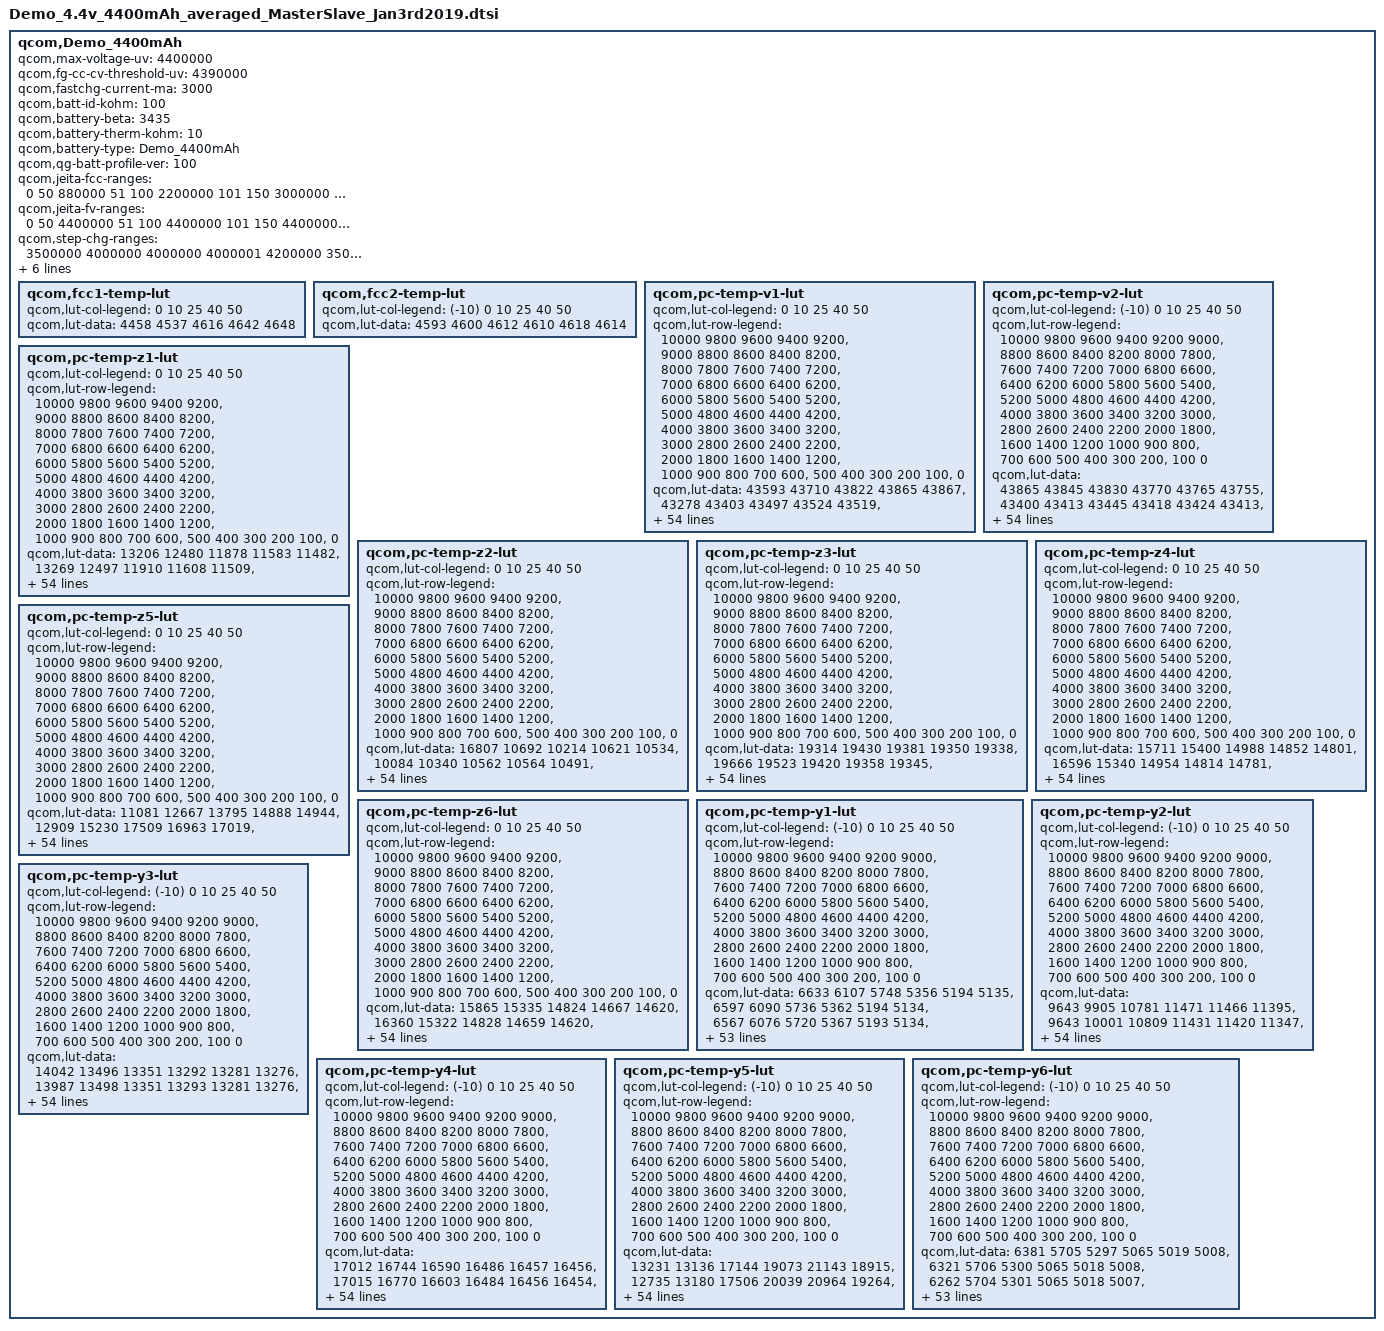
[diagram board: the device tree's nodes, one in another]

qcom,Demo_4400mAh {
    /* Demo */
    qcom,max-voltage-uv = <4400000>;
    qcom,fg-cc-cv-threshold-uv = <4390000>;
    qcom,fastchg-current-ma = <3000>;
    qcom,batt-id-kohm = <100>;
    qcom,battery-beta = <3435>;
    qcom,battery-therm-kohm = <10>;
    qcom,battery-type = "Demo_4400mAh";
    qcom,qg-batt-profile-ver = <100>;

	qcom,jeita-fcc-ranges = <0  50  880000
				51 100  2200000
				101 150  3000000
				151 450  4400000
				451 600  2200000>;

	qcom,jeita-fv-ranges = <0   50  4400000
				51 100  4400000
				101 150  4400000
				151 450  4400000
				451 600  4100000>;

	qcom,step-chg-ranges = <3500000  4000000  4000000
				4000001  4200000  3500000
				4200001  4400000  2500000>;
	qcom,ocv-based-step-chg;

	/* COOL = 10 degc, WARM = 45 degC */
	qcom,jeita-soft-thresholds = <0x2AEE 0x0FB3>;
	/* COLD = 0 degC, HOT = 60 degC*/
	qcom,jeita-hard-thresholds = <0x3733 0x0A34>;
	/* COOL hys = 13 degC, WARM hys = 42 degC */
	qcom,jeita-soft-hys-thresholds = <0x279A 0x1124>;
	qcom,jeita-soft-fcc-ua = <2200000 2200000>;
	qcom,jeita-soft-fv-uv = <4400000 4100000>;
	qcom,fcc1-temp-lut {
		qcom,lut-col-legend = <0 10 25 40 50>;
		qcom,lut-data = <4458 4537 4616 4642 4648>;
	};

	qcom,fcc2-temp-lut {
		qcom,lut-col-legend = <(-10) 0 10 25 40 50>;
		qcom,lut-data = <4593 4600 4612 4610 4618 4614>;
	};

	qcom,pc-temp-v1-lut {
		qcom,lut-col-legend = <0 10 25 40 50>;
		qcom,lut-row-legend = <10000 9800 9600 9400 9200>,
			<9000 8800 8600 8400 8200>,
			<8000 7800 7600 7400 7200>,
			<7000 6800 6600 6400 6200>,
			<6000 5800 5600 5400 5200>,
			<5000 4800 4600 4400 4200>,
			<4000 3800 3600 3400 3200>,
			<3000 2800 2600 2400 2200>,
			<2000 1800 1600 1400 1200>,
			<1000 900 800 700 600>,
			<500 400 300 200 100>,
			<0>;
		qcom,lut-data = <43593 43710 43822 43865 43867>,
			<43278 43403 43497 43524 43519>,
			<43007 43121 43220 43244 43242>,
			<42753 42870 42964 42991 42990>,
			<42511 42627 42716 42746 42749>,
			<42282 42387 42472 42504 42509>,
			<42060 42154 42233 42267 42272>,
			<41848 41931 41998 42031 42037>,
			<41642 41716 41768 41799 41807>,
			<41441 41507 41544 41571 41582>,
			<41244 41306 41328 41347 41359>,
			<41047 41108 41121 41127 41138>,
			<40854 40907 40912 40912 40921>,
			<40642 40707 40702 40705 40713>,
			<40358 40483 40494 40504 40510>,
			<40060 40203 40286 40313 40318>,
			<39877 39966 40076 40129 40135>,
			<39759 39837 39902 39955 39960>,
			<39650 39741 39766 39793 39795>,
			<39534 39626 39637 39639 39637>,
			<39419 39499 39503 39495 39489>,
			<39305 39359 39357 39351 39345>,
			<39190 39199 39149 39166 39165>,
			<39075 39023 38857 38909 38915>,
			<38960 38828 38661 38700 38705>,
			<38844 38613 38572 38585 38581>,
			<38722 38483 38503 38495 38484>,
			<38595 38420 38430 38403 38390>,
			<38491 38374 38359 38313 38303>,
			<38408 38333 38294 38235 38224>,
			<38341 38298 38234 38167 38154>,
			<38291 38265 38181 38107 38090>,
			<38252 38232 38134 38056 38035>,
			<38222 38201 38092 38010 37983>,
			<38202 38172 38056 37969 37935>,
			<38181 38143 38024 37933 37891>,
			<38155 38112 37990 37892 37843>,
			<38123 38083 37957 37849 37793>,
			<38082 38041 37915 37797 37734>,
			<38026 37964 37845 37726 37658>,
			<37953 37858 37743 37634 37561>,
			<37844 37745 37633 37527 37452>,
			<37702 37613 37504 37398 37326>,
			<37553 37454 37348 37243 37171>,
			<37396 37293 37188 37085 37016>,
			<37265 37179 37079 36988 36928>,
			<37224 37146 37051 36960 36902>,
			<37194 37120 37032 36941 36882>,
			<37167 37104 37015 36927 36868>,
			<37139 37086 36991 36901 36837>,
			<37042 36976 36857 36737 36650>,
			<36672 36598 36470 36334 36237>,
			<36117 36046 35910 35772 35673>,
			<35362 35287 35145 35006 34903>,
			<34197 34121 33968 33826 33718>,
			<30000 30000 30000 30000 30000>;
	};

	qcom,pc-temp-v2-lut {
		qcom,lut-col-legend = <(-10) 0 10 25 40 50>;
		qcom,lut-row-legend = <10000 9800 9600 9400 9200 9000>,
			<8800 8600 8400 8200 8000 7800>,
			<7600 7400 7200 7000 6800 6600>,
			<6400 6200 6000 5800 5600 5400>,
			<5200 5000 4800 4600 4400 4200>,
			<4000 3800 3600 3400 3200 3000>,
			<2800 2600 2400 2200 2000 1800>,
			<1600 1400 1200 1000 900 800>,
			<700 600 500 400 300 200>,
			<100 0>;
		qcom,lut-data = <43865 43845 43830 43770 43765 43755>,
			<43400 43413 43445 43418 43424 43413>,
			<42997 43037 43103 43101 43115 43104>,
			<42665 42728 42811 42824 42840 42830>,
			<42385 42468 42560 42580 42595 42587>,
			<42134 42222 42316 42341 42356 42348>,
			<41909 41988 42074 42103 42118 42111>,
			<41695 41758 41839 41870 41884 41878>,
			<41462 41503 41613 41641 41654 41648>,
			<41233 41249 41394 41417 41428 41422>,
			<41091 41087 41191 41199 41206 41200>,
			<41019 40995 41008 40989 40988 40983>,
			<40912 40875 40812 40781 40776 40770>,
			<40482 40576 40572 40568 40571 40566>,
			<39911 40196 40318 40355 40372 40367>,
			<39630 39939 40092 40149 40181 40177>,
			<39459 39735 39881 39948 39999 39994>,
			<39295 39550 39714 39781 39827 39821>,
			<39126 39377 39591 39647 39664 39658>,
			<38962 39202 39457 39510 39507 39501>,
			<38799 39014 39248 39346 39360 39354>,
			<38642 38821 39000 39167 39210 39204>,
			<38513 38641 38801 38966 39012 39010>,
			<38402 38465 38631 38734 38757 38758>,
			<38309 38328 38485 38546 38559 38559>,
			<38232 38235 38360 38416 38430 38430>,
			<38166 38162 38249 38309 38326 38325>,
			<38104 38101 38145 38213 38229 38228>,
			<38047 38048 38050 38128 38143 38140>,
			<37995 38001 37981 38051 38065 38061>,
			<37946 37959 37930 37981 37995 37989>,
			<37898 37920 37889 37918 37931 37924>,
			<37851 37881 37856 37864 37878 37871>,
			<37803 37843 37828 37816 37827 37819>,
			<37755 37806 37799 37775 37771 37759>,
			<37706 37769 37769 37739 37712 37689>,
			<37652 37727 37735 37698 37645 37610>,
			<37593 37677 37698 37648 37567 37514>,
			<37527 37619 37652 37589 37486 37419>,
			<37456 37553 37584 37518 37411 37341>,
			<37379 37474 37491 37434 37334 37267>,
			<37302 37377 37376 37342 37248 37182>,
			<37225 37261 37245 37226 37138 37075>,
			<37144 37126 37100 37092 37008 36945>,
			<37058 36992 36965 36930 36856 36798>,
			<36970 36900 36871 36872 36810 36756>,
			<36929 36867 36840 36855 36802 36749>,
			<36881 36842 36815 36842 36788 36738>,
			<36814 36810 36781 36817 36769 36718>,
			<36709 36751 36715 36778 36723 36669>,
			<36492 36605 36558 36625 36536 36444>,
			<36101 36215 36161 36189 36065 35966>,
			<35511 35602 35539 35583 35445 35337>,
			<34647 34730 34674 34766 34599 34480>,
			<33223 33339 33371 33530 33340 33177>,
			<30321 29646 29628 28797 29074 28973>;
	};

	qcom,pc-temp-z1-lut {
		qcom,lut-col-legend = <0 10 25 40 50>;
		qcom,lut-row-legend = <10000 9800 9600 9400 9200>,
			<9000 8800 8600 8400 8200>,
			<8000 7800 7600 7400 7200>,
			<7000 6800 6600 6400 6200>,
			<6000 5800 5600 5400 5200>,
			<5000 4800 4600 4400 4200>,
			<4000 3800 3600 3400 3200>,
			<3000 2800 2600 2400 2200>,
			<2000 1800 1600 1400 1200>,
			<1000 900 800 700 600>,
			<500 400 300 200 100>,
			<0>;
		qcom,lut-data = <13206 12480 11878 11583 11482>,
			<13269 12497 11910 11608 11509>,
			<13266 12498 11904 11604 11507>,
			<13261 12478 11895 11598 11501>,
			<13248 12463 11883 11592 11499>,
			<13225 12454 11874 11588 11498>,
			<13207 12449 11864 11584 11496>,
			<13190 12443 11858 11579 11494>,
			<13176 12438 11856 11577 11493>,
			<13166 12434 11856 11575 11492>,
			<13157 12427 11857 11574 11491>,
			<13142 12422 11861 11573 11490>,
			<13109 12415 11862 11572 11489>,
			<13079 12401 11846 11570 11488>,
			<13057 12386 11827 11567 11488>,
			<13037 12366 11826 11567 11487>,
			<13026 12355 11829 11568 11488>,
			<13014 12363 11832 11570 11489>,
			<13009 12377 11840 11573 11491>,
			<13017 12381 11848 11575 11492>,
			<13028 12385 11853 11575 11493>,
			<13030 12389 11857 11576 11494>,
			<13029 12398 11859 11577 11495>,
			<13029 12408 11860 11579 11497>,
			<13042 12412 11862 11582 11499>,
			<13060 12414 11867 11585 11501>,
			<13064 12417 11872 11587 11504>,
			<13072 12421 11875 11590 11507>,
			<13076 12425 11877 11593 11509>,
			<13086 12431 11881 11597 11511>,
			<13098 12436 11888 11600 11514>,
			<13100 12441 11894 11603 11516>,
			<13104 12447 11897 11608 11518>,
			<13105 12451 11898 11612 11521>,
			<13105 12456 11903 11615 11523>,
			<13109 12467 11912 11617 11525>,
			<13124 12476 11916 11619 11527>,
			<13151 12486 11917 11625 11530>,
			<13159 12497 11918 11630 11533>,
			<13156 12511 11927 11634 11536>,
			<13156 12525 11941 11637 11539>,
			<13181 12536 11945 11640 11542>,
			<13214 12543 11945 11644 11544>,
			<13204 12534 11951 11647 11545>,
			<13197 12531 11961 11649 11547>,
			<13199 12533 11962 11654 11549>,
			<13204 12542 11958 11655 11549>,
			<13170 12535 11962 11655 11549>,
			<13212 12545 11968 11656 11551>,
			<13187 12555 11964 11658 11555>,
			<13207 12547 11972 11666 11560>,
			<13187 12580 11984 11675 11567>,
			<13209 12595 11997 11684 11576>,
			<13255 12620 12017 11698 11586>,
			<13255 12620 12017 11698 11586>,
			<13255 12620 12017 11698 11586>;
	};

	qcom,pc-temp-z2-lut {
		qcom,lut-col-legend = <0 10 25 40 50>;
		qcom,lut-row-legend = <10000 9800 9600 9400 9200>,
			<9000 8800 8600 8400 8200>,
			<8000 7800 7600 7400 7200>,
			<7000 6800 6600 6400 6200>,
			<6000 5800 5600 5400 5200>,
			<5000 4800 4600 4400 4200>,
			<4000 3800 3600 3400 3200>,
			<3000 2800 2600 2400 2200>,
			<2000 1800 1600 1400 1200>,
			<1000 900 800 700 600>,
			<500 400 300 200 100>,
			<0>;
		qcom,lut-data = <16807 10692 10214 10621 10534>,
			<10084 10340 10562 10564 10491>,
			<10152 10364 10577 10621 10493>,
			<10192 10326 10558 10654 10658>,
			<10226 10285 10528 10627 10601>,
			<10253 10254 10494 10592 10547>,
			<10265 10226 10457 10553 10532>,
			<10270 10206 10435 10516 10524>,
			<10272 10188 10436 10510 10489>,
			<10262 10181 10441 10518 10414>,
			<10240 10179 10447 10523 10385>,
			<10213 10178 10457 10534 10394>,
			<10173 10186 10468 10544 10408>,
			<10134 10213 10490 10542 10426>,
			<10095 10238 10513 10533 10449>,
			<10062 10257 10514 10512 10462>,
			<10059 10279 10509 10468 10470>,
			<10075 10318 10509 10448 10480>,
			<10091 10365 10535 10465 10506>,
			<10103 10394 10565 10493 10538>,
			<10114 10411 10584 10514 10550>,
			<10125 10428 10598 10535 10557>,
			<10136 10454 10593 10562 10591>,
			<10148 10475 10573 10607 10709>,
			<10163 10467 10561 10622 10777>,
			<10180 10435 10554 10587 10774>,
			<10201 10423 10550 10557 10787>,
			<10229 10440 10566 10583 10749>,
			<10252 10460 10600 10636 10602>,
			<10268 10471 10607 10648 10484>,
			<10283 10479 10594 10593 10401>,
			<10300 10488 10584 10551 10357>,
			<10319 10498 10581 10553 10363>,
			<10336 10508 10580 10558 10383>,
			<10352 10519 10589 10568 10414>,
			<10369 10532 10620 10593 10470>,
			<10395 10547 10641 10624 10528>,
			<10427 10564 10651 10671 10594>,
			<10437 10584 10662 10707 10642>,
			<10338 10611 10695 10712 10653>,
			<10255 10636 10736 10711 10659>,
			<10281 10645 10742 10722 10663>,
			<10334 10650 10738 10749 10671>,
			<10423 10664 10742 10760 10665>,
			<11474 10742 10765 10768 10650>,
			<15092 10949 10832 10732 10650>,
			<14674 10971 10831 10732 10667>,
			<15316 10984 10830 10727 10677>,
			<14764 11173 10832 10752 10725>,
			<15671 19194 10849 10857 10859>,
			<15114 12650 10940 10793 10686>,
			<12745 11170 10916 10633 10499>,
			<13826 11349 10885 10578 10423>,
			<12390 11112 10801 10526 10346>,
			<12390 11112 10801 10526 10346>,
			<12390 11112 10801 10526 10346>;
	};

	qcom,pc-temp-z3-lut {
		qcom,lut-col-legend = <0 10 25 40 50>;
		qcom,lut-row-legend = <10000 9800 9600 9400 9200>,
			<9000 8800 8600 8400 8200>,
			<8000 7800 7600 7400 7200>,
			<7000 6800 6600 6400 6200>,
			<6000 5800 5600 5400 5200>,
			<5000 4800 4600 4400 4200>,
			<4000 3800 3600 3400 3200>,
			<3000 2800 2600 2400 2200>,
			<2000 1800 1600 1400 1200>,
			<1000 900 800 700 600>,
			<500 400 300 200 100>,
			<0>;
		qcom,lut-data = <19314 19430 19381 19350 19338>,
			<19666 19523 19420 19358 19345>,
			<19740 19600 19440 19371 19348>,
			<19774 19615 19463 19399 19378>,
			<19766 19619 19464 19400 19382>,
			<19744 19618 19464 19401 19383>,
			<19726 19615 19463 19400 19384>,
			<19708 19610 19460 19399 19384>,
			<19695 19602 19455 19396 19381>,
			<19694 19595 19449 19389 19370>,
			<19696 19591 19446 19383 19363>,
			<19697 19586 19444 19380 19362>,
			<19693 19573 19440 19377 19361>,
			<19694 19549 19432 19375 19359>,
			<19717 19541 19422 19372 19357>,
			<19750 19543 19419 19368 19354>,
			<19748 19546 19419 19363 19349>,
			<19704 19526 19418 19358 19344>,
			<19664 19492 19415 19355 19341>,
			<19641 19486 19411 19352 19339>,
			<19625 19492 19407 19349 19336>,
			<19623 19498 19404 19347 19333>,
			<19624 19507 19406 19348 19334>,
			<19625 19517 19416 19355 19340>,
			<19634 19519 19420 19358 19343>,
			<19645 19519 19411 19352 19351>,
			<19651 19519 19402 19345 19364>,
			<19656 19519 19406 19355 19370>,
			<19657 19518 19418 19384 19378>,
			<19652 19516 19426 19395 19377>,
			<19645 19513 19431 19392 19372>,
			<19639 19511 19433 19388 19366>,
			<19633 19508 19431 19383 19361>,
			<19624 19505 19426 19377 19357>,
			<19611 19502 19421 19371 19351>,
			<19597 19499 19417 19365 19345>,
			<19587 19495 19413 19361 19341>,
			<19578 19489 19409 19359 19338>,
			<19560 19486 19406 19357 19337>,
			<19478 19485 19404 19354 19337>,
			<19410 19484 19402 19350 19338>,
			<19406 19482 19399 19348 19338>,
			<19403 19477 19395 19348 19337>,
			<19312 19471 19394 19350 19340>,
			<19259 19459 19391 19352 19343>,
			<19257 19424 19379 19341 19332>,
			<19257 19417 19374 19336 19327>,
			<19257 19416 19368 19334 19324>,
			<19257 19343 19365 19330 19315>,
			<19257 19267 19364 19321 19308>,
			<19257 19259 19349 19331 19328>,
			<19258 19324 19351 19345 19340>,
			<19257 19264 19346 19346 19342>,
			<19257 19260 19347 19347 19342>,
			<19257 19260 19347 19347 19342>,
			<19257 19260 19347 19347 19342>;
	};

	qcom,pc-temp-z4-lut {
		qcom,lut-col-legend = <0 10 25 40 50>;
		qcom,lut-row-legend = <10000 9800 9600 9400 9200>,
			<9000 8800 8600 8400 8200>,
			<8000 7800 7600 7400 7200>,
			<7000 6800 6600 6400 6200>,
			<6000 5800 5600 5400 5200>,
			<5000 4800 4600 4400 4200>,
			<4000 3800 3600 3400 3200>,
			<3000 2800 2600 2400 2200>,
			<2000 1800 1600 1400 1200>,
			<1000 900 800 700 600>,
			<500 400 300 200 100>,
			<0>;
		qcom,lut-data = <15711 15400 14988 14852 14801>,
			<16596 15340 14954 14814 14781>,
			<16325 15573 14926 14776 14746>,
			<15993 15355 14992 14852 14812>,
			<15783 15152 14910 14820 14791>,
			<15607 15048 14847 14784 14764>,
			<15470 14969 14809 14762 14742>,
			<15362 14909 14779 14743 14725>,
			<15272 14863 14753 14730 14719>,
			<15194 14827 14732 14721 14716>,
			<15127 14798 14721 14713 14713>,
			<15063 14775 14716 14706 14706>,
			<15001 14755 14711 14699 14699>,
			<14951 14737 14706 14692 14692>,
			<14915 14733 14700 14686 14685>,
			<14886 14736 14695 14681 14680>,
			<14862 14739 14690 14678 14677>,
			<14841 14735 14683 14674 14673>,
			<14825 14726 14670 14669 14668>,
			<14814 14713 14660 14665 14663>,
			<14804 14695 14661 14663 14661>,
			<14791 14686 14663 14663 14660>,
			<14773 14694 14690 14675 14670>,
			<14757 14711 14784 14748 14738>,
			<14741 14749 14829 14796 14785>,
			<14730 14823 14821 14794 14771>,
			<14733 14850 14807 14787 14743>,
			<14748 14835 14785 14765 14722>,
			<14758 14811 14755 14719 14700>,
			<14764 14790 14733 14695 14688>,
			<14768 14770 14714 14686 14682>,
			<14765 14752 14702 14681 14677>,
			<14755 14736 14696 14677 14672>,
			<14744 14723 14691 14674 14668>,
			<14733 14712 14689 14673 14668>,
			<14723 14702 14687 14672 14669>,
			<14715 14694 14684 14672 14670>,
			<14707 14687 14681 14673 14672>,
			<14710 14684 14679 14674 14673>,
			<14785 14685 14680 14677 14676>,
			<14850 14686 14683 14681 14678>,
			<14851 14684 14682 14680 14677>,
			<14847 14679 14674 14671 14669>,
			<14933 14676 14671 14670 14670>,
			<14951 14670 14667 14670 14672>,
			<14899 14662 14649 14654 14653>,
			<14896 14661 14645 14651 14651>,
			<14889 14653 14640 14640 14640>,
			<14883 14730 14634 14629 14630>,
			<14877 14805 14629 14628 14626>,
			<14875 14818 14654 14637 14630>,
			<14895 14762 14663 14637 14634>,
			<14911 14834 14672 14638 14635>,
			<14925 14847 14674 14640 14639>,
			<14925 14847 14674 14640 14639>,
			<14925 14847 14674 14640 14639>;
	};

	qcom,pc-temp-z5-lut {
		qcom,lut-col-legend = <0 10 25 40 50>;
		qcom,lut-row-legend = <10000 9800 9600 9400 9200>,
			<9000 8800 8600 8400 8200>,
			<8000 7800 7600 7400 7200>,
			<7000 6800 6600 6400 6200>,
			<6000 5800 5600 5400 5200>,
			<5000 4800 4600 4400 4200>,
			<4000 3800 3600 3400 3200>,
			<3000 2800 2600 2400 2200>,
			<2000 1800 1600 1400 1200>,
			<1000 900 800 700 600>,
			<500 400 300 200 100>,
			<0>;
		qcom,lut-data = <11081 12667 13795 14888 14944>,
			<12909 15230 17509 16963 17019>,
			<13609 15075 19046 19943 19027>,
			<14151 15825 17773 19010 19553>,
			<14419 16714 18505 19385 19928>,
			<14605 17430 19310 19898 20579>,
			<14766 18145 20094 20392 21600>,
			<14904 18834 20857 20913 22584>,
			<15075 19499 21677 21291 22386>,
			<15412 20304 22700 21498 21187>,
			<15863 21832 23705 21585 20654>,
			<16167 23207 24738 21948 21127>,
			<16374 23338 25330 22549 21919>,
			<16730 23090 25274 23328 22922>,
			<19049 23312 24921 24071 23988>,
			<22325 25602 24868 24062 24159>,
			<22514 27499 25332 23563 23764>,
			<20300 25272 26696 23373 23543>,
			<18722 21216 31360 24307 24454>,
			<18395 20973 34720 25616 25767>,
			<18275 24693 34743 26261 26291>,
			<18633 29807 34481 26778 26648>,
			<20079 40474 35776 27343 26917>,
			<22269 51645 40057 27504 25922>,
			<26758 52326 41418 26761 24773>,
			<33167 49230 32452 22249 22655>,
			<41030 46049 23635 17534 20826>,
			<50950 42060 23597 18700 21969>,
			<54734 38428 24888 24037 24367>,
			<53874 36567 26989 28456 25903>,
			<52458 35264 31442 31571 26979>,
			<51102 35014 35811 34188 28226>,
			<49302 35302 39230 36696 30237>,
			<46651 35769 41968 38619 32237>,
			<41121 36964 43508 38883 32640>,
			<35910 38464 44603 38784 32718>,
			<33957 38748 44792 38582 32711>,
			<32774 38512 43259 37836 32104>,
			<31002 38498 41133 36535 31129>,
			<25537 40831 39280 33415 29842>,
			<21293 43547 37337 28763 28125>,
			<21162 42540 35366 27153 27161>,
			<21153 39016 33397 26946 26648>,
			<15010 36825 32523 27479 27586>,
			<11609 36223 32290 28078 29125>,
			<11831 30449 32816 25886 25653>,
			<11811 26604 29750 23932 22434>,
			<11745 27111 27200 24839 22947>,
			<11741 18655 26792 25060 22559>,
			<11745 12284 27989 22194 21224>,
			<11771 11779 20581 23100 27339>,
			<11773 15289 18719 25089 27195>,
			<11664 11846 17191 23705 25053>,
			<11526 11544 16831 21753 21952>,
			<11526 11544 16831 21753 21952>,
			<11526 11544 16831 21753 21952>;
	};

	qcom,pc-temp-z6-lut {
		qcom,lut-col-legend = <0 10 25 40 50>;
		qcom,lut-row-legend = <10000 9800 9600 9400 9200>,
			<9000 8800 8600 8400 8200>,
			<8000 7800 7600 7400 7200>,
			<7000 6800 6600 6400 6200>,
			<6000 5800 5600 5400 5200>,
			<5000 4800 4600 4400 4200>,
			<4000 3800 3600 3400 3200>,
			<3000 2800 2600 2400 2200>,
			<2000 1800 1600 1400 1200>,
			<1000 900 800 700 600>,
			<500 400 300 200 100>,
			<0>;
		qcom,lut-data = <15865 15335 14824 14667 14620>,
			<16360 15322 14828 14659 14620>,
			<16232 15444 14822 14648 14606>,
			<16065 15335 14859 14695 14650>,
			<15938 15229 14820 14680 14642>,
			<15818 15168 14789 14665 14632>,
			<15723 15119 14768 14654 14624>,
			<15646 15079 14751 14645 14616>,
			<15582 15046 14736 14637 14610>,
			<15534 15019 14722 14629 14604>,
			<15493 14999 14716 14622 14598>,
			<15448 14981 14713 14617 14594>,
			<15396 14954 14709 14613 14590>,
			<15358 14924 14698 14608 14586>,
			<15340 14914 14686 14603 14582>,
			<15327 14913 14683 14598 14577>,
			<15304 14913 14681 14594 14573>,
			<15267 14902 14678 14590 14569>,
			<15240 14884 14672 14586 14565>,
			<15229 14880 14667 14583 14562>,
			<15221 14880 14667 14581 14560>,
			<15217 14880 14667 14580 14558>,
			<15214 14887 14680 14586 14562>,
			<15213 14901 14726 14621 14595>,
			<15215 14923 14748 14644 14618>,
			<15220 14956 14742 14641 14616>,
			<15228 14968 14733 14635 14612>,
			<15238 14963 14727 14631 14608>,
			<15244 14955 14722 14628 14603>,
			<15247 14948 14717 14625 14598>,
			<15248 14939 14714 14620 14593>,
			<15247 14932 14710 14616 14588>,
			<15243 14926 14706 14612 14584>,
			<15238 14921 14703 14607 14580>,
			<15231 14917 14701 14604 14576>,
			<15224 14914 14699 14600 14573>,
			<15220 14912 14697 14599 14572>,
			<15217 14911 14696 14598 14571>,
			<15216 14911 14694 14598 14571>,
			<15214 14914 14696 14598 14572>,
			<15213 14920 14697 14599 14574>,
			<15217 14922 14697 14598 14573>,
			<15223 14923 14694 14595 14570>,
			<15223 14923 14694 14595 14572>,
			<15214 14921 14693 14597 14575>,
			<15199 14907 14682 14585 14562>,
			<15197 14904 14679 14582 14557>,
			<15195 14901 14673 14576 14552>,
			<15193 14897 14670 14569 14543>,
			<15194 14897 14670 14565 14538>,
			<15202 14904 14675 14574 14551>,
			<15217 14917 14684 14584 14561>,
			<15236 14928 14689 14589 14565>,
			<15258 14945 14697 14593 14569>,
			<15258 14945 14697 14593 14569>,
			<15258 14945 14697 14593 14569>;
	};

	qcom,pc-temp-y1-lut {
		qcom,lut-col-legend = <(-10) 0 10 25 40 50>;
		qcom,lut-row-legend = <10000 9800 9600 9400 9200 9000>,
			<8800 8600 8400 8200 8000 7800>,
			<7600 7400 7200 7000 6800 6600>,
			<6400 6200 6000 5800 5600 5400>,
			<5200 5000 4800 4600 4400 4200>,
			<4000 3800 3600 3400 3200 3000>,
			<2800 2600 2400 2200 2000 1800>,
			<1600 1400 1200 1000 900 800>,
			<700 600 500 400 300 200>,
			<100 0>;
		qcom,lut-data = <6633 6107 5748 5356 5194 5135>,
			<6597 6090 5736 5362 5194 5134>,
			<6567 6076 5720 5367 5193 5134>,
			<6545 6064 5705 5370 5193 5134>,
			<6532 6055 5694 5371 5192 5133>,
			<6529 6052 5691 5370 5191 5132>,
			<6540 6054 5694 5367 5189 5131>,
			<6552 6056 5697 5363 5188 5130>,
			<6556 6048 5696 5362 5186 5129>,
			<6558 6036 5693 5360 5184 5129>,
			<6561 6034 5693 5359 5182 5128>,
			<6569 6038 5695 5355 5182 5127>,
			<6578 6044 5697 5352 5181 5126>,
			<6584 6049 5699 5350 5180 5125>,
			<6589 6057 5701 5348 5179 5125>,
			<6584 6066 5703 5351 5179 5124>,
			<6561 6077 5707 5360 5180 5124>,
			<6550 6080 5707 5363 5180 5125>,
			<6558 6075 5705 5361 5180 5125>,
			<6564 6070 5704 5358 5180 5125>,
			<6561 6072 5705 5360 5180 5125>,
			<6553 6078 5709 5364 5181 5126>,
			<6550 6079 5711 5366 5182 5127>,
			<6551 6074 5713 5368 5183 5127>,
			<6556 6068 5713 5368 5185 5128>,
			<6567 6073 5706 5369 5187 5129>,
			<6580 6082 5698 5371 5189 5130>,
			<6581 6083 5698 5374 5191 5132>,
			<6578 6081 5705 5378 5194 5133>,
			<6571 6079 5710 5381 5196 5135>,
			<6542 6070 5716 5384 5198 5138>,
			<6517 6062 5720 5387 5201 5140>,
			<6535 6062 5723 5392 5204 5142>,
			<6569 6065 5725 5398 5208 5144>,
			<6571 6068 5725 5400 5210 5146>,
			<6549 6074 5722 5399 5211 5147>,
			<6535 6077 5718 5399 5213 5149>,
			<6535 6069 5713 5403 5214 5149>,
			<6535 6060 5709 5406 5216 5150>,
			<6540 6060 5712 5407 5217 5153>,
			<6558 6062 5720 5406 5219 5155>,
			<6554 6070 5716 5409 5220 5155>,
			<6544 6073 5718 5417 5222 5157>,
			<6574 6103 5732 5424 5226 5159>,
			<6593 6099 5732 5431 5230 5162>,
			<6597 6104 5748 5438 5236 5166>,
			<6578 6103 5732 5444 5238 5167>,
			<6585 6086 5723 5438 5240 5167>,
			<6579 6107 5726 5439 5239 5167>,
			<6603 6121 5741 5450 5238 5165>,
			<6621 6142 5742 5449 5238 5167>,
			<6632 6124 5743 5451 5243 5171>,
			<6664 6138 5766 5476 5255 5177>,
			<6753 6166 5797 5495 5266 5186>,
			<6753 6166 5797 5495 5266 5186>,
			<6753 6166 5797 5495 5266 5186>;
	};

	qcom,pc-temp-y2-lut {
		qcom,lut-col-legend = <(-10) 0 10 25 40 50>;
		qcom,lut-row-legend = <10000 9800 9600 9400 9200 9000>,
			<8800 8600 8400 8200 8000 7800>,
			<7600 7400 7200 7000 6800 6600>,
			<6400 6200 6000 5800 5600 5400>,
			<5200 5000 4800 4600 4400 4200>,
			<4000 3800 3600 3400 3200 3000>,
			<2800 2600 2400 2200 2000 1800>,
			<1600 1400 1200 1000 900 800>,
			<700 600 500 400 300 200>,
			<100 0>;
		qcom,lut-data = <9643 9905 10781 11471 11466 11395>,
			<9643 10001 10809 11431 11420 11347>,
			<9643 10084 10825 11389 11374 11300>,
			<9782 10149 10833 11347 11327 11256>,
			<9899 10192 10835 11306 11281 11216>,
			<9971 10207 10835 11268 11236 11182>,
			<9995 10187 10820 11229 11186 11150>,
			<9994 10169 10798 11193 11144 11126>,
			<9917 10292 10772 11166 11118 11114>,
			<9745 10539 10741 11142 11100 11104>,
			<9698 10589 10744 11118 11096 11090>,
			<9704 10522 10806 11089 11098 11051>,
			<9708 10478 10858 11076 11098 11025>,
			<9699 10540 10931 11086 11086 11022>,
			<9686 10651 11007 11107 11077 11025>,
			<9680 10736 11024 11128 11100 11034>,
			<9677 10813 11040 11155 11147 11052>,
			<9675 10898 11068 11195 11178 11068>,
			<9674 11017 11149 11270 11201 11093>,
			<9673 11091 11207 11340 11234 11131>,
			<9673 10926 11190 11379 11369 11257>,
			<9672 10537 11159 11406 11540 11425>,
			<9671 10299 11167 11408 11538 11435>,
			<9671 9915 11231 11403 11427 11338>,
			<9671 9731 11283 11400 11370 11285>,
			<9670 9719 11311 11415 11367 11311>,
			<9669 9714 11327 11441 11368 11349>,
			<9668 9709 11331 11469 11380 11363>,
			<9668 9703 11333 11502 11415 11372>,
			<9667 9697 11332 11520 11454 11394>,
			<9667 9691 11327 11533 11509 11460>,
			<9666 9685 11319 11539 11539 11508>,
			<9665 9681 11288 11534 11556 11539>,
			<9665 9678 11237 11527 11573 11568>,
			<9664 9675 11192 11525 11572 11559>,
			<9664 9672 11146 11522 11552 11497>,
			<9664 9670 11095 11514 11527 11448>,
			<9663 9668 11041 11489 11485 11423>,
			<9663 9666 10972 11456 11454 11404>,
			<9662 9665 10782 11421 11446 11392>,
			<9662 9664 10416 11381 11438 11377>,
			<9661 9663 9938 11351 11405 11332>,
			<9661 9662 9790 11314 11427 11312>,
			<9661 9662 9756 11324 11441 11347>,
			<9660 9660 9707 11245 11437 11383>,
			<9660 9660 9686 11146 11288 11148>,
			<9660 9659 9680 11091 11199 11119>,
			<9659 9659 9674 11063 11229 11073>,
			<9659 9658 9670 11027 11235 11091>,
			<9659 9658 9667 11000 11250 11142>,
			<9658 9658 9665 10964 11231 11072>,
			<9658 9657 9663 10866 11162 11014>,
			<9657 9657 9659 10762 11095 10917>,
			<9654 9656 9657 10685 10961 10796>,
			<9654 9656 9657 10685 10961 10796>,
			<9654 9656 9657 10685 10961 10796>;
	};

	qcom,pc-temp-y3-lut {
		qcom,lut-col-legend = <(-10) 0 10 25 40 50>;
		qcom,lut-row-legend = <10000 9800 9600 9400 9200 9000>,
			<8800 8600 8400 8200 8000 7800>,
			<7600 7400 7200 7000 6800 6600>,
			<6400 6200 6000 5800 5600 5400>,
			<5200 5000 4800 4600 4400 4200>,
			<4000 3800 3600 3400 3200 3000>,
			<2800 2600 2400 2200 2000 1800>,
			<1600 1400 1200 1000 900 800>,
			<700 600 500 400 300 200>,
			<100 0>;
		qcom,lut-data = <14042 13496 13351 13292 13281 13276>,
			<13987 13498 13351 13293 13281 13276>,
			<13889 13500 13352 13294 13281 13277>,
			<13781 13501 13353 13295 13281 13277>,
			<13695 13502 13354 13296 13281 13278>,
			<13664 13502 13356 13297 13281 13278>,
			<13660 13502 13358 13298 13282 13279>,
			<13657 13502 13359 13298 13283 13280>,
			<13622 13496 13362 13299 13283 13280>,
			<13555 13478 13366 13300 13284 13280>,
			<13533 13460 13368 13301 13284 13281>,
			<13533 13420 13368 13302 13285 13282>,
			<13531 13398 13367 13303 13286 13283>,
			<13515 13407 13361 13304 13286 13283>,
			<13490 13419 13355 13305 13287 13284>,
			<13476 13417 13351 13305 13288 13284>,
			<13463 13405 13347 13306 13290 13284>,
			<13458 13393 13345 13306 13291 13285>,
			<13455 13383 13344 13304 13290 13286>,
			<13454 13373 13343 13302 13290 13288>,
			<13453 13364 13338 13302 13290 13288>,
			<13452 13357 13330 13302 13290 13287>,
			<13450 13352 13325 13300 13288 13285>,
			<13445 13341 13322 13296 13282 13279>,
			<13442 13331 13319 13293 13280 13276>,
			<13451 13313 13316 13291 13280 13276>,
			<13466 13298 13313 13290 13280 13277>,
			<13481 13299 13311 13290 13279 13276>,
			<13497 13306 13309 13289 13279 13276>,
			<13515 13315 13308 13289 13279 13276>,
			<13537 13329 13307 13289 13278 13275>,
			<13560 13345 13307 13289 13278 13274>,
			<13584 13361 13308 13289 13278 13274>,
			<13609 13378 13312 13290 13279 13275>,
			<13638 13400 13314 13291 13280 13276>,
			<13670 13427 13317 13291 13280 13276>,
			<13703 13456 13319 13291 13280 13276>,
			<13738 13486 13323 13291 13279 13276>,
			<13774 13517 13326 13292 13279 13275>,
			<13808 13552 13328 13292 13279 13276>,
			<13840 13589 13330 13293 13279 13277>,
			<13878 13624 13334 13293 13280 13278>,
			<13921 13668 13344 13294 13280 13278>,
			<13919 13663 13343 13294 13280 13277>,
			<13984 13735 13359 13291 13276 13274>,
			<14070 13828 13384 13297 13280 13277>,
			<14128 13878 13396 13298 13284 13281>,
			<14189 13937 13433 13302 13286 13284>,
			<14256 13990 13475 13304 13289 13286>,
			<14338 14045 13518 13311 13291 13287>,
			<14422 14104 13571 13314 13289 13283>,
			<14547 14166 13623 13312 13287 13282>,
			<14738 14296 13776 13320 13291 13286>,
			<15494 14470 13995 13332 13295 13291>,
			<15494 14470 13995 13332 13295 13291>,
			<15494 14470 13995 13332 13295 13291>;
	};

	qcom,pc-temp-y4-lut {
		qcom,lut-col-legend = <(-10) 0 10 25 40 50>;
		qcom,lut-row-legend = <10000 9800 9600 9400 9200 9000>,
			<8800 8600 8400 8200 8000 7800>,
			<7600 7400 7200 7000 6800 6600>,
			<6400 6200 6000 5800 5600 5400>,
			<5200 5000 4800 4600 4400 4200>,
			<4000 3800 3600 3400 3200 3000>,
			<2800 2600 2400 2200 2000 1800>,
			<1600 1400 1200 1000 900 800>,
			<700 600 500 400 300 200>,
			<100 0>;
		qcom,lut-data = <17012 16744 16590 16486 16457 16456>,
			<17015 16770 16603 16484 16456 16454>,
			<17015 16797 16622 16482 16454 16452>,
			<17013 16822 16641 16481 16453 16450>,
			<17008 16841 16654 16480 16452 16448>,
			<17001 16850 16658 16480 16452 16447>,
			<16977 16852 16655 16480 16452 16446>,
			<16959 16852 16652 16481 16452 16446>,
			<17031 16850 16650 16482 16453 16447>,
			<17198 16855 16648 16485 16455 16448>,
			<17302 16914 16657 16488 16457 16450>,
			<17383 17135 16701 16492 16460 16451>,
			<17418 17265 16736 16497 16462 16453>,
			<17188 17110 16750 16507 16468 16456>,
			<16871 16883 16756 16519 16474 16460>,
			<16833 16816 16743 16528 16478 16464>,
			<16834 16788 16716 16538 16482 16469>,
			<16832 16781 16717 16554 16488 16475>,
			<16810 16771 16748 16592 16501 16482>,
			<16778 16754 16770 16619 16520 16491>,
			<16740 16726 16727 16618 16551 16517>,
			<16701 16684 16641 16615 16584 16548>,
			<16692 16648 16591 16595 16571 16541>,
			<16691 16613 16557 16519 16498 16487>,
			<16691 16599 16535 16473 16458 16455>,
			<16690 16613 16523 16465 16451 16449>,
			<16689 16631 16513 16461 16448 16446>,
			<16688 16634 16498 16461 16449 16447>,
			<16687 16635 16481 16463 16452 16450>,
			<16686 16635 16478 16465 16456 16454>,
			<16687 16631 16482 16467 16463 16462>,
			<16690 16629 16487 16470 16471 16470>,
			<16694 16631 16494 16471 16480 16480>,
			<16698 16635 16502 16471 16487 16488>,
			<16701 16640 16512 16474 16487 16489>,
			<16703 16647 16525 16481 16482 16484>,
			<16705 16654 16539 16484 16475 16478>,
			<16704 16664 16555 16482 16462 16462>,
			<16704 16671 16569 16480 16454 16450>,
			<16705 16672 16580 16478 16455 16451>,
			<16707 16672 16590 16477 16458 16456>,
			<16714 16667 16602 16483 16463 16462>,
			<16719 16655 16602 16486 16462 16461>,
			<16710 16626 16586 16474 16454 16453>,
			<16706 16615 16587 16469 16439 16433>,
			<16725 16619 16599 16478 16446 16441>,
			<16736 16633 16617 16490 16454 16451>,
			<16756 16646 16633 16505 16468 16474>,
			<16783 16668 16657 16524 16497 16507>,
			<16805 16703 16707 16556 16524 16533>,
			<16806 16728 16744 16562 16510 16493>,
			<16791 16704 16738 16539 16467 16458>,
			<16796 16694 16726 16563 16477 16461>,
			<16993 16708 16745 16604 16504 16482>,
			<16993 16708 16745 16604 16504 16482>,
			<16993 16708 16745 16604 16504 16482>;
	};

	qcom,pc-temp-y5-lut {
		qcom,lut-col-legend = <(-10) 0 10 25 40 50>;
		qcom,lut-row-legend = <10000 9800 9600 9400 9200 9000>,
			<8800 8600 8400 8200 8000 7800>,
			<7600 7400 7200 7000 6800 6600>,
			<6400 6200 6000 5800 5600 5400>,
			<5200 5000 4800 4600 4400 4200>,
			<4000 3800 3600 3400 3200 3000>,
			<2800 2600 2400 2200 2000 1800>,
			<1600 1400 1200 1000 900 800>,
			<700 600 500 400 300 200>,
			<100 0>;
		qcom,lut-data = <13231 13136 17144 19073 21143 18915>,
			<12735 13180 17506 20039 20964 19264>,
			<12785 13771 17983 20617 20667 19847>,
			<13188 14622 18466 20893 20341 20474>,
			<13754 15441 18848 20951 20076 20956>,
			<14355 15970 19028 20865 19943 21116>,
			<16377 16692 19104 20472 19690 21133>,
			<18192 17202 19135 19956 19369 21120>,
			<16720 16301 19613 19474 18994 20687>,
			<13279 14407 20602 18890 18468 19785>,
			<12928 13930 20170 18285 18067 19315>,
			<16945 14850 16991 17526 17775 19087>,
			<19600 16085 15082 16885 17414 18808>,
			<17840 19442 16719 16437 16668 18322>,
			<15112 23013 18964 16090 16011 17734>,
			<14374 22849 19320 15830 16143 17079>,
			<14126 21384 19023 15581 16638 16366>,
			<14199 20933 19320 15529 16692 16160>,
			<14657 21837 21684 15473 15652 16191>,
			<15012 22589 23637 15491 14851 16234>,
			<14843 22263 23844 17820 15481 16265>,
			<14340 21256 23940 22086 16908 16307>,
			<13784 19724 24153 23946 18567 16893>,
			<13005 16617 24597 24915 20828 19360>,
			<12635 14303 24897 25206 22183 21342>,
			<12646 13117 24999 24085 22758 22464>,
			<12660 12433 24943 22690 23053 23096>,
			<12690 12365 24153 22311 22642 22494>,
			<12835 12346 22263 22119 21453 20793>,
			<12983 12372 20691 22155 20372 19348>,
			<13168 12683 19287 22486 19287 17946>,
			<13351 13038 18630 22663 18787 17243>,
			<13485 13231 19030 23385 19469 17538>,
			<13616 13399 19690 24633 20794 18260>,
			<13832 13675 19865 24767 22170 19671>,
			<14173 14099 19905 24216 23645 22150>,
			<14324 14344 19978 23764 24017 23091>,
			<14330 14409 20191 23565 23343 22758>,
			<14331 14457 20361 23343 22529 22293>,
			<14174 14590 19656 22811 21912 22020>,
			<13651 14715 17807 21908 21324 21780>,
			<13289 14694 15543 20691 20918 21507>,
			<13194 14662 14653 20345 20783 21568>,
			<12988 14214 14075 22664 22318 23270>,
			<13185 14002 14396 19325 20132 21399>,
			<13281 13886 14385 21391 20296 18581>,
			<13608 13565 13918 19410 20332 20101>,
			<13749 13748 14179 19163 19043 18673>,
			<13894 13888 14537 17648 18343 17496>,
			<14384 13944 14601 17901 17982 16906>,
			<14541 14505 15038 18342 18207 16602>,
			<14312 13968 14361 19730 21472 19907>,
			<13962 14038 14147 19925 22967 20824>,
			<12644 14015 14007 20826 24192 25021>,
			<12644 14015 14007 20826 24192 25021>,
			<12644 14015 14007 20826 24192 25021>;
	};

	qcom,pc-temp-y6-lut {
		qcom,lut-col-legend = <(-10) 0 10 25 40 50>;
		qcom,lut-row-legend = <10000 9800 9600 9400 9200 9000>,
			<8800 8600 8400 8200 8000 7800>,
			<7600 7400 7200 7000 6800 6600>,
			<6400 6200 6000 5800 5600 5400>,
			<5200 5000 4800 4600 4400 4200>,
			<4000 3800 3600 3400 3200 3000>,
			<2800 2600 2400 2200 2000 1800>,
			<1600 1400 1200 1000 900 800>,
			<700 600 500 400 300 200>,
			<100 0>;
		qcom,lut-data = <6381 5705 5297 5065 5019 5008>,
			<6321 5706 5300 5065 5018 5008>,
			<6262 5704 5301 5065 5018 5007>,
			<6207 5699 5300 5065 5017 5007>,
			<6159 5693 5298 5065 5017 5007>,
			<6121 5686 5295 5065 5017 5007>,
			<6090 5676 5290 5065 5017 5008>,
			<6065 5664 5286 5065 5018 5008>,
			<6040 5649 5283 5066 5019 5009>,
			<6019 5634 5281 5067 5019 5009>,
			<6017 5635 5282 5068 5020 5010>,
			<6036 5663 5289 5069 5021 5011>,
			<6048 5680 5294 5071 5023 5012>,
			<5974 5649 5293 5074 5024 5013>,
			<5871 5601 5288 5078 5027 5015>,
			<5856 5584 5284 5080 5029 5016>,
			<5854 5573 5275 5085 5031 5018>,
			<5853 5567 5275 5090 5034 5020>,
			<5850 5560 5281 5099 5038 5023>,
			<5847 5550 5286 5105 5042 5027>,
			<5839 5538 5270 5105 5051 5034>,
			<5830 5522 5239 5103 5060 5042>,
			<5827 5510 5223 5097 5055 5039>,
			<5827 5497 5213 5072 5030 5018>,
			<5829 5492 5208 5057 5017 5007>,
			<5838 5499 5205 5054 5014 5006>,
			<5854 5511 5203 5053 5014 5005>,
			<5867 5522 5202 5053 5014 5005>,
			<5882 5536 5201 5055 5015 5006>,
			<5897 5551 5202 5056 5016 5007>,
			<5915 5568 5207 5058 5018 5009>,
			<5934 5587 5214 5059 5020 5011>,
			<5955 5608 5224 5061 5024 5014>,
			<5977 5632 5237 5062 5027 5017>,
			<6002 5659 5251 5065 5027 5018>,
			<6029 5691 5265 5067 5026 5017>,
			<6057 5723 5282 5069 5024 5015>,
			<6085 5756 5304 5070 5021 5011>,
			<6114 5790 5327 5071 5018 5007>,
			<6141 5827 5349 5073 5018 5008>,
			<6170 5864 5370 5074 5020 5010>,
			<6203 5894 5395 5078 5022 5013>,
			<6243 5930 5423 5082 5022 5013>,
			<6251 5928 5421 5079 5020 5010>,
			<6304 5983 5461 5079 5014 5003>,
			<6382 6063 5528 5091 5020 5008>,
			<6429 6107 5561 5098 5025 5014>,
			<6483 6157 5615 5109 5031 5022>,
			<6545 6207 5674 5119 5041 5033>,
			<6620 6261 5739 5137 5050 5041>,
			<6696 6319 5803 5142 5045 5027>,
			<6797 6367 5859 5140 5032 5017>,
			<6961 6468 6000 5170 5039 5021>,
			<7680 6620 6195 5212 5052 5033>,
			<7680 6620 6195 5212 5052 5033>,
			<7680 6620 6195 5212 5052 5033>;
	};

};
